# ionuc505 register map
Registers are 32-bit, access not given, no defined reset value unless marked. A register's access mark holds for its fields unless they carry their own. Addresses are absolute; registers are grouped by the start of their names; [hi:lo] are bit positions; {n}, {i} and the like mark numbered series; 'fields as' and 'values as' point back to an identical list.

## TIMER23
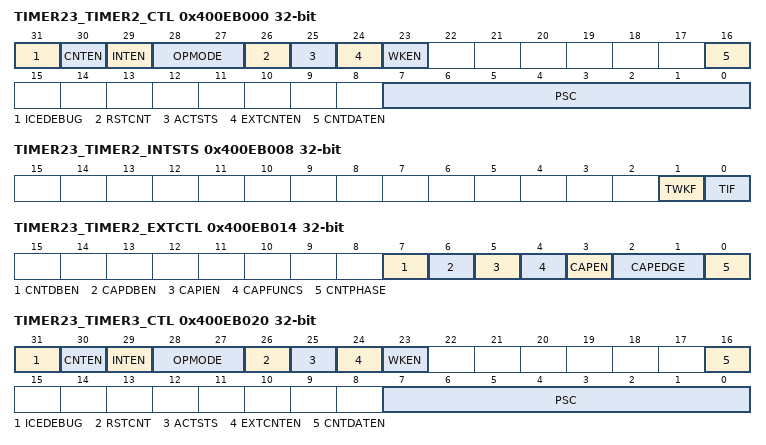
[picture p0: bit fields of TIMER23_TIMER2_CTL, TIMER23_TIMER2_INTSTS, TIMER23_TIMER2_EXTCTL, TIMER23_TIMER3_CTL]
0x400EB000 TIMER23_TIMER2_CTL
  [31] ICEDEBUG, [30] CNTEN, [29] INTEN, [28:27] OPMODE, [26] RSTCNT, [25] ACTSTS, [24] EXTCNTEN, [23] WKEN, [16] CNTDATEN, [7:0] PSC
0x400EB004 TIMER23_TIMER2_CMP
  [23:0] CMPDAT
0x400EB008 TIMER23_TIMER2_INTSTS
  [1] TWKF, [0] TIF
0x400EB00C TIMER23_TIMER2_CNT
  [23:0] CNT
0x400EB010 TIMER23_TIMER2_CAP
  [23:0] CAPDAT
0x400EB014 TIMER23_TIMER2_EXTCTL
  [7] CNTDBEN, [6] CAPDBEN, [5] CAPIEN, [4] CAPFUNCS, [3] CAPEN, [2:1] CAPEDGE, [0] CNTPHASE
0x400EB018 TIMER23_TIMER2_EINTSTS
  [0] CAPIF
0x400EB020 TIMER23_TIMER3_CTL
  fields as TIMER23_TIMER2_CTL
0x400EB024 TIMER23_TIMER3_CMP
  [23:0] CMPDAT
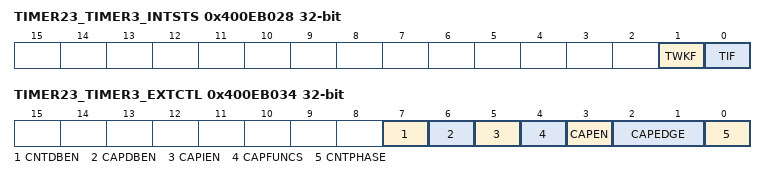
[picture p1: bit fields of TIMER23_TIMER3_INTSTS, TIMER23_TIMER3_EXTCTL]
0x400EB028 TIMER23_TIMER3_INTSTS
  [1] TWKF, [0] TIF
0x400EB02C TIMER23_TIMER3_CNT
  [23:0] CNT
0x400EB030 TIMER23_TIMER3_CAP
  [23:0] CAPDAT
0x400EB034 TIMER23_TIMER3_EXTCTL
  fields as TIMER23_TIMER2_EXTCTL
0x400EB038 TIMER23_TIMER3_EINTSTS
  [0] CAPIF

## PWM
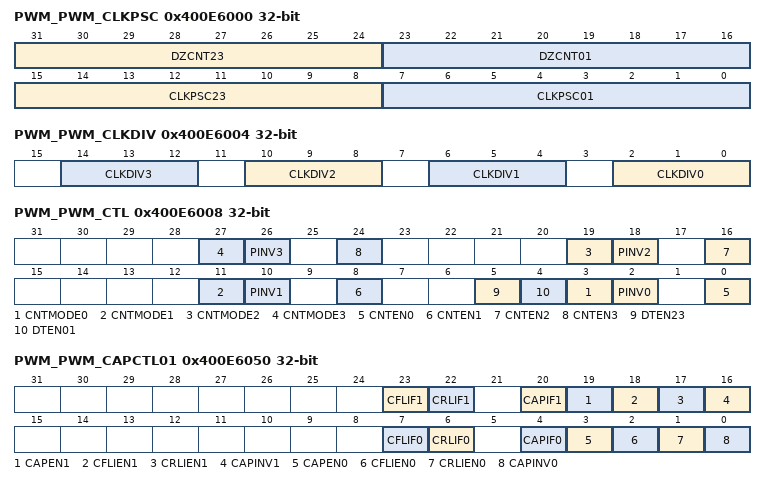
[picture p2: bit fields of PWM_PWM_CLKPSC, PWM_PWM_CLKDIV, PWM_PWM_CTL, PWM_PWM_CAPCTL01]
0x400E6000 PWM_PWM_CLKPSC
  [31:24] DZCNT23, [23:16] DZCNT01, [15:8] CLKPSC23, [7:0] CLKPSC01
0x400E6004 PWM_PWM_CLKDIV
  [4n+2:4n] CLKDIV{n} (n=0..3)
0x400E6008 PWM_PWM_CTL
  [8n+3] CNTMODE{n} (n=0..3), [8n+2] PINV{n} (n=0..3), [8n] CNTEN{n} (n=0..3), [5] DTEN23, [4] DTEN01
{0x400E600C+0xC*i} PWM_PWM_PERIOD{i} (i=0..3)
  [15:0] PERIOD
{0x400E6010+0xC*i} PWM_PWM_CMPDAT{i} (i=0..3)
  [15:0] CMP
{0x400E6014+0xC*i} PWM_PWM_CNT{i} (i=0..3)
  [15:0] CNT
0x400E6040 PWM_PWM_INTEN
  [3:0] PIEN
0x400E6044 PWM_PWM_INTSTS
  [3:0] PIF
0x400E6050 PWM_PWM_CAPCTL01
  [23] CFLIF1, [22] CRLIF1, [20] CAPIF1, [19] CAPEN1, [18] CFLIEN1, [17] CRLIEN1, [16] CAPINV1, [7] CFLIF0, [6] CRLIF0, [4] CAPIF0, [3] CAPEN0, [2] CFLIEN0, [1] CRLIEN0, [0] CAPINV0
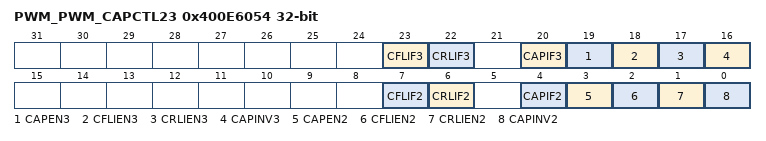
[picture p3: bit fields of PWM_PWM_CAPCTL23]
0x400E6054 PWM_PWM_CAPCTL23
  [23] CFLIF3, [22] CRLIF3, [20] CAPIF3, [19] CAPEN3, [18] CFLIEN3, [17] CRLIEN3, [16] CAPINV3, [7] CFLIF2, [6] CRLIF2, [4] CAPIF2, [3] CAPEN2, [2] CFLIEN2, [1] CRLIEN2, [0] CAPINV2
{0x400E6058+8i} PWM_PWM_RCAPDAT{i} (i=0..3)
  [15:0] RCAPDAT
{0x400E605C+8i} PWM_PWM_FCAPDAT{i} (i=0..3)
  [15:0] FCAPDAT
0x400E6078 PWM_PWM_CAPINEN
  [0] CAPINEN
0x400E607C PWM_PWM_POEN
  [3:0] POEN

## WDT
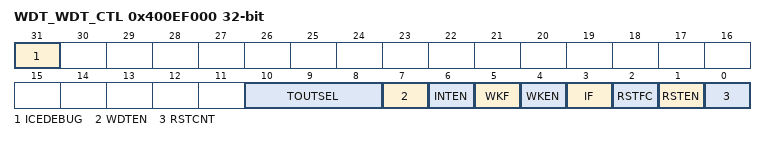
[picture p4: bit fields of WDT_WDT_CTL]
0x400EF000 WDT_WDT_CTL
  [31] ICEDEBUG, [10:8] TOUTSEL, [7] WDTEN, [6] INTEN, [5] WKF, [4] WKEN, [3] IF, [2] RSTFC, [1] RSTEN, [0] RSTCNT
0x400EF004 WDT_WDT_ALTCTL
  [1:0] RSTDSEL
0x400EF010 WDT_WDT_RSTSTS
  [2] RSTF

## WWDT
0x400EF100 WWDT_WWDT_RLDCNT
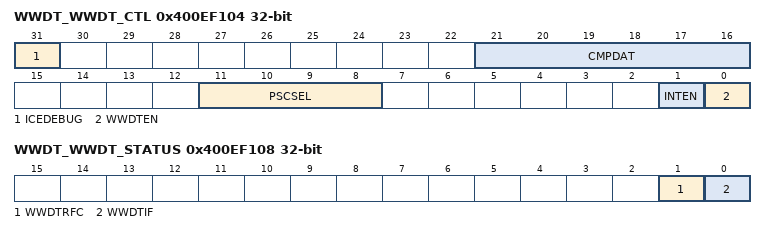
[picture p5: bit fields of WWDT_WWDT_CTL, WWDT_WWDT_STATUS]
0x400EF104 WWDT_WWDT_CTL
  [31] ICEDEBUG, [21:16] CMPDAT, [11:8] PSCSEL, [1] INTEN, [0] WWDTEN
0x400EF108 WWDT_WWDT_STATUS
  [1] WWDTRFC, [0] WWDTIF
0x400EF10C WWDT_WWDT_CNT
  [5:0] CNTDAT
0x400EF118 WWDT_WWDT_RSTSTS
  [1] WWDTRF

## RTC
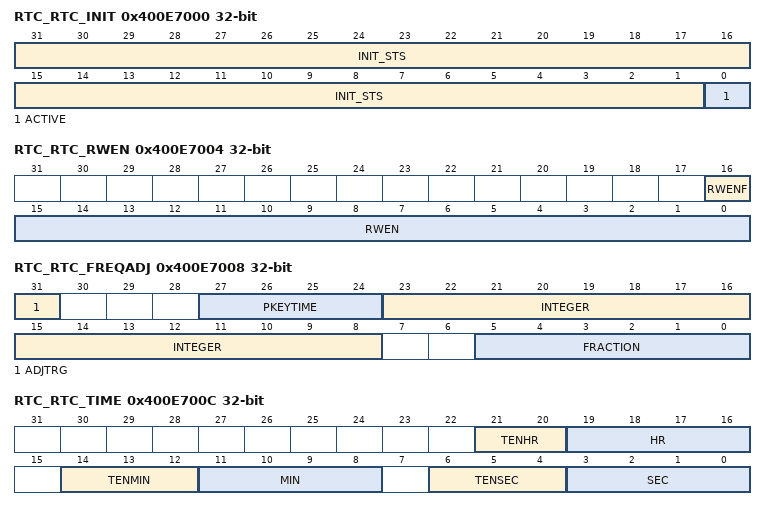
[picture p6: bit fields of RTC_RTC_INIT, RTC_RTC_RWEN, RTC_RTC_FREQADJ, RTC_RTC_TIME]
0x400E7000 RTC_RTC_INIT
  [31:1] INIT_STS, [0] ACTIVE
0x400E7004 RTC_RTC_RWEN
  [16] RWENF, [15:0] RWEN
0x400E7008 RTC_RTC_FREQADJ
  [31] ADJTRG, [27:24] PKEYTIME, [23:8] INTEGER, [5:0] FRACTION
0x400E700C RTC_RTC_TIME
  [21:20] TENHR, [19:16] HR, [14:12] TENMIN, [11:8] MIN, [6:4] TENSEC, [3:0] SEC
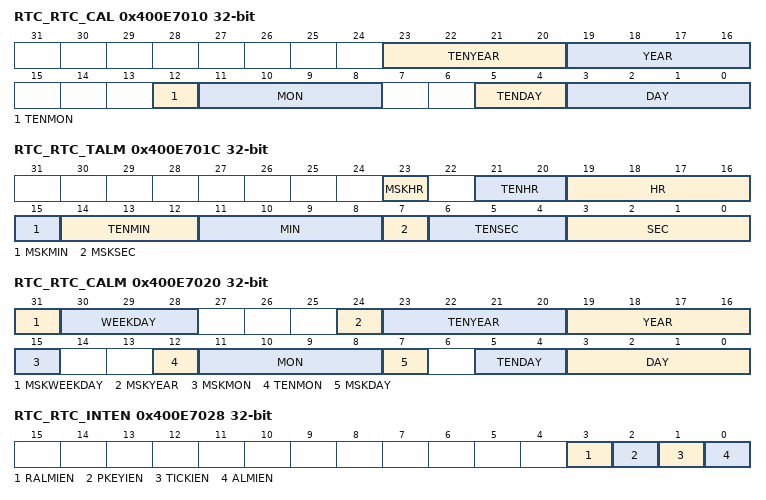
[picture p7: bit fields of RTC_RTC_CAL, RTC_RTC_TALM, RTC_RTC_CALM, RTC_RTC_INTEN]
0x400E7010 RTC_RTC_CAL
  [23:20] TENYEAR, [19:16] YEAR, [12] TENMON, [11:8] MON, [5:4] TENDAY, [3:0] DAY
0x400E7014 RTC_RTC_CLKFMT
  [0] 24HEN
0x400E7018 RTC_RTC_WEEKDAY
  [2:0] WEEKDAY
0x400E701C RTC_RTC_TALM
  [23] MSKHR, [21:20] TENHR, [19:16] HR, [15] MSKMIN, [14:12] TENMIN, [11:8] MIN, [7] MSKSEC, [6:4] TENSEC, [3:0] SEC
0x400E7020 RTC_RTC_CALM
  [31] MSKWEEKDAY, [30:28] WEEKDAY, [24] MSKYEAR, [23:20] TENYEAR, [19:16] YEAR, [15] MSKMON, [12] TENMON, [11:8] MON, [7] MSKDAY, [5:4] TENDAY, [3:0] DAY
0x400E7024 RTC_RTC_LEAPYEAR
  [0] LEAPYEAR
0x400E7028 RTC_RTC_INTEN
  [3] RALMIEN, [2] PKEYIEN, [1] TICKIEN, [0] ALMIEN
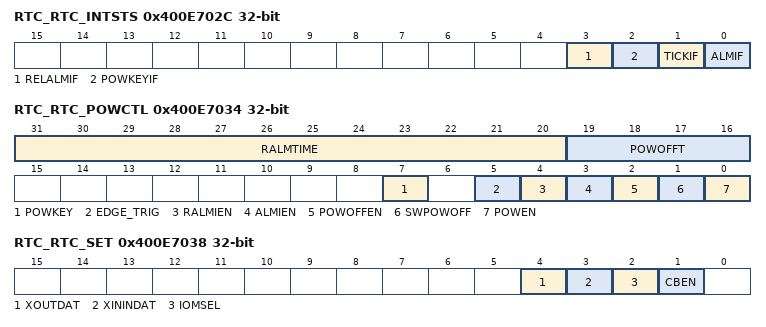
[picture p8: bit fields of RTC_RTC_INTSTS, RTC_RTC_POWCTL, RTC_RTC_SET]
0x400E702C RTC_RTC_INTSTS
  [3] RELALMIF, [2] POWKEYIF, [1] TICKIF, [0] ALMIF
0x400E7030 RTC_RTC_TICK
  [2:0] TICKSEL
0x400E7034 RTC_RTC_POWCTL
  [31:20] RALMTIME, [19:16] POWOFFT, [7] POWKEY, [5] EDGE_TRIG, [4] RALMIEN, [3] ALMIEN, [2] POWOFFEN, [1] SWPOWOFF, [0] POWEN
0x400E7038 RTC_RTC_SET
  [4] XOUTDAT, [3] XININDAT, [2] IOMSEL, [1] CBEN
0x400E703C RTC_RTC_CLKSRC
  [0] CKSRC
0x400E7040 RTC_RTC_CALCNT
0x400E7044 RTC_RTC_SYNC
  [0] SYNC
{0x400E7054+4i} RTC_RTC_SPR{i} (i=0..7)
